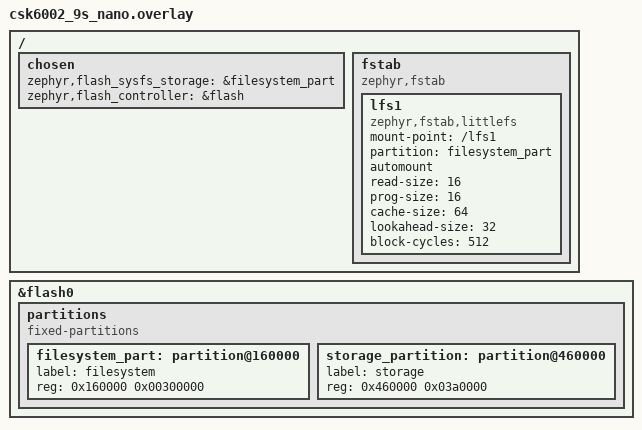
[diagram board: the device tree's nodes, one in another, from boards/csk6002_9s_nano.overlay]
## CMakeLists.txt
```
#
# Copyright (c) 2019 Peter Bigot Consulting, LLC
#
# SPDX-License-Identifier: Apache-2.0
#

cmake_minimum_required(VERSION 3.20.0)

set(SUPPORT_BOARDS csk6012_nano csk6011a_nano)
if(NOT ${BOARD} IN_LIST SUPPORT_BOARDS)
    message("Please choose one of the following boards:")
    foreach(item ${SUPPORT_BOARDS})
        message(STATUS ${item})
    endforeach()
    message(FATAL_ERROR "\nThe project does not support the ${BOARD}")
endif()

find_package(Zephyr REQUIRED HINTS $ENV{ZEPHYR_BASE})
project(littlefs)

# add_subdirectory(csk_sqlite3)

FILE(GLOB app_sources src/*.c)
target_sources(app PRIVATE ${app_sources})
```

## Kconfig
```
# Copyright (c) 2019 Peter Bigot Consulting, LLC
# SPDX-License-Identifier: Apache-2.0

mainmenu "littlefs sample"

config APP_WIPE_STORAGE
	bool "Option to clear the flash area before mounting"
	help
	  Use this to force an existing file system to be created.

config CSK_SQLITE
	bool "CSK_SQLITE3 support"

source "Kconfig.zephyr"
```

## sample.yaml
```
sample:
  description: sqlite3_littefs sample, the simplest Zephyr
    application
  name: sqlite3_littefs
tests:
  sample.board.csk6.subsys.sqlite3_littefs:
    tags: csk6
    platform_allow: csk6012_c3_nano
    harness: console
    timeout: 20
    harness_config:
      type: multi_line
      regex:
        - "CSK sqlite3 test complete!"
```

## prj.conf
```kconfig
#
# Copyright (c) 2019 Peter Bigot Consulting, LLC
#
# SPDX-License-Identifier: Apache-2.0
#
CONFIG_MAIN_STACK_SIZE=4096
CONFIG_CSK_HEAP=y
CONFIG_HEAP_MEM_POOL_SIZE=92160
CONFIG_DEBUG=y

CONFIG_LOG=y

CONFIG_FLASH=y
CONFIG_FLASH_MAP=y
CONFIG_FLASH_PAGE_LAYOUT=y

CONFIG_FILE_SYSTEM=y
CONFIG_FILE_SYSTEM_LITTLEFS=y
CONFIG_CSK_SQLITE=y

CONFIG_ENTROPY_GENERATOR=y
CONFIG_ENTROPY_CSK6_RNG=y

CONFIG_PRINTK_SYNC=y
```

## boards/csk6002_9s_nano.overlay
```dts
/*
 * Copyright (c) 2020 Circuit Dojo LLC
 *
 * SPDX-License-Identifier: Apache-2.0
 */

/delete-node/ &storage_partition;

/ {
	chosen {
		/*
		 * shared memory reserved for the inter-processor communication
		 */
		zephyr,flash_sysfs_storage = &filesystem_part;
		zephyr,flash_controller = &flash;
	};
	
	fstab {
		compatible = "zephyr,fstab";
		lfs1: lfs1 {
			compatible = "zephyr,fstab,littlefs";
			mount-point = "/lfs1";
			partition = <&filesystem_part>;
			automount ;
			// no-format;
			read-size = <16>;
			prog-size = <16>;
			cache-size = <64>;
			lookahead-size = <32>;
			block-cycles = <512>;
		};
	};

};

 
&flash0 {
	partitions {
		compatible = "fixed-partitions";
		#address-cells = <1>;
		#size-cells = <1>;
		filesystem_part: partition@160000 {
			label = "filesystem";
			reg = <0x160000 0x00300000>;
		};
		/*
		 * Reserve the final 640 KiB for file system partition
		 */
		storage_partition: partition@460000 {
			label = "storage";
			reg = <0x460000 0x03a0000>;
		};


	};
};
```

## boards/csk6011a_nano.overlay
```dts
/*
 * Copyright (c) 2023 Anhui(Shenzhen) Listenai Co., Ltd.
 *
 * SPDX-License-Identifier: Apache-2.0
 */
/delete-node/ &storage_partition;

/ {
	chosen {
		/*
		 * shared memory reserved for the inter-processor communication
		 */
		zephyr,flash_sysfs_storage = &filesystem_part;
		zephyr,flash_controller = &flash;
	};

	fstab {
		compatible = "zephyr,fstab";
		lfs1: lfs1 {
			compatible = "zephyr,fstab,littlefs";
			mount-point = "/lfs1";
			partition = <&filesystem_part>;
			automount ;
			// no-format;
			read-size = <16>;
			prog-size = <16>;
			cache-size = <64>;
			lookahead-size = <32>;
			block-cycles = <512>;
		};
	};

};


&flash0 {
	partitions {
		compatible = "fixed-partitions";
		#address-cells = <1>;
		#size-cells = <1>;
		filesystem_part: partition@160000 {
			label = "filesystem";
			reg = <0x160000 0x00300000>;
		};
		/*
		 * Reserve the final 640 KiB for file system partition
		 */
		storage_partition: partition@460000 {
			label = "storage";
			reg = <0x460000 0x03a0000>;
		};


	};
};
```

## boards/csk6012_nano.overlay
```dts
/*
 * Copyright (c) 2023 Anhui(Shenzhen) Listenai Co., Ltd.
 *
 * SPDX-License-Identifier: Apache-2.0
 */

/delete-node/ &storage_partition;

/ {
	chosen {
		/*
		 * shared memory reserved for the inter-processor communication
		 */
		zephyr,flash_sysfs_storage = &filesystem_part;
		zephyr,flash_controller = &flash;
	};

	fstab {
		compatible = "zephyr,fstab";
		lfs1: lfs1 {
			compatible = "zephyr,fstab,littlefs";
			mount-point = "/lfs1";
			partition = <&filesystem_part>;
			automount ;
			// no-format;
			read-size = <16>;
			prog-size = <16>;
			cache-size = <64>;
			lookahead-size = <32>;
			block-cycles = <512>;
		};
	};

};


&flash0 {
	partitions {
		compatible = "fixed-partitions";
		#address-cells = <1>;
		#size-cells = <1>;
		filesystem_part: partition@160000 {
			label = "filesystem";
			reg = <0x160000 0x00300000>;
		};
		/*
		 * Reserve the final 640 KiB for file system partition
		 */
		storage_partition: partition@460000 {
			label = "storage";
			reg = <0x460000 0x03a0000>;
		};


	};
};
```

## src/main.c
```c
/*
 * Copyright (c) 2023 Anhui(Shenzhen) Listenai Co., Ltd.
 *
 * SPDX-License-Identifier: Apache-2.0
 */
/* Sample which uses the filesystem API with littlefs */

#include "sqlite3.h"

#include <stdio.h>

#include <device.h>
#include <fs/fs.h>
#include <fs/littlefs.h>
#include <storage/flash_map.h>
#include <zephyr.h>

/* Matches LFS_NAME_MAX */
#define MAX_PATH_LEN 255

#define PARTITION_NODE DT_NODELABEL(lfs1)

#if DT_NODE_EXISTS(PARTITION_NODE)
FS_FSTAB_DECLARE_ENTRY(PARTITION_NODE);
#else  /* PARTITION_NODE */
FS_LITTLEFS_DECLARE_DEFAULT_CONFIG(storage);
static struct fs_mount_t lfs_storage_mnt = {
	.type = FS_LITTLEFS,
	.fs_data = &storage,
	.storage_dev = (void *)FLASH_AREA_ID(storage),
	.mnt_point = "/lfs",
};
#endif /* PARTITION_NODE */

const char *data = "Callback function called";
static int callback(void *data, int argc, char **argv, char **azColName)
{
	int i;
	printk("%s: ", (const char *)data);
	for (i = 0; i < argc; i++) {
		printk("%s = %s\n", azColName[i], argv[i] ? argv[i] : "NULL");
	}
	printk("\n");
	return 0;
}

int db_open(const char *filename, sqlite3 **db)
{
	int rc = sqlite3_open(filename, db);
	if (rc) {
		printk("Can't open database: %s\n", sqlite3_errmsg(*db));
		return rc;
	} else {
		printk("Opened database successfully\n");
	}
	return rc;
}

char *zErrMsg = 0;
int db_exec(sqlite3 *db, const char *sql)
{
	printk("%s\n", sql);

	uint32_t start = k_cycle_get_32();
	int rc = sqlite3_exec(db, sql, callback, (void *)data, &zErrMsg);
	if (rc != SQLITE_OK) {
		printk("SQL error: %s\n", zErrMsg);
		sqlite3_free(zErrMsg);
	} else {
		printk("Operation done successfully\n");
	}
	uint32_t time =
		(double)(k_cycle_get_32() - start) / sys_clock_hw_cycles_per_sec() * 1000 * 1000;
	printk("Time taken: %d us\n", time);
	return rc;
}

void main(void)
{
	sqlite3 *db1;
	sqlite3 *db2;
	struct fs_mount_t *mp =
#if DT_NODE_EXISTS(PARTITION_NODE)
		&FS_FSTAB_ENTRY(PARTITION_NODE)
#else
		&lfs_storage_mnt
#endif
		;
	int rc = 0;
	/* Do not mount if auto-mount has been enabled */
#if !DT_NODE_EXISTS(PARTITION_NODE) ||                                                             \
	!(FSTAB_ENTRY_DT_MOUNT_FLAGS(PARTITION_NODE) & FS_MOUNT_FLAG_AUTOMOUNT)
	rc = fs_mount(mp);
	if (rc < 0) {
		printk("FAIL: mount id %" PRIuPTR " at %s: %d\n", (uintptr_t)mp->storage_dev,
		       mp->mnt_point, rc);
		return;
	}
	printk("%s mount: %d\n", mp->mnt_point, rc);
#else
	printk("%s automounted\n", mp->mnt_point);
#endif

	struct fs_file_t file;

	fs_file_t_init(&file);

	sqlite3_initialize();

	struct fs_dirent dirent;
	if (fs_stat("/lfs1/test1.db", &dirent) >= 0) {
		rc = fs_unlink("/lfs1/test1.db");
		printk("fs_unlink: rc = %d\n", rc);
	}
	if (fs_stat("/lfs1/test2.db", &dirent) >= 0) {
		rc = fs_unlink("/lfs1/test2.db");
		printk("fs_unlink: rc = %d\n", rc);
	}

	if (db_open("/lfs1/test1.db", &db1))
		return;
	if (db_open("/lfs1/test2.db", &db2))
		return;

	rc = db_exec(db1, "CREATE TABLE test1 (id INTEGER, content);");
	if (rc != SQLITE_OK) {
		sqlite3_close(db1);
		sqlite3_close(db2);
		return;
	}
	rc = db_exec(db2, "CREATE TABLE test2 (id INTEGER, content);");
	if (rc != SQLITE_OK) {
		sqlite3_close(db1);
		sqlite3_close(db2);
		return;
	}

	rc = db_exec(db1, "INSERT INTO test1 VALUES (1, 'Hello, World from test1');");
	if (rc != SQLITE_OK) {
		sqlite3_close(db1);
		sqlite3_close(db2);
		return;
	}
	// rc = db_exec(db1, "INSERT INTO test1 VALUES (2, 'over, World from test1');");
	// if (rc != SQLITE_OK) {
	// 	sqlite3_close(db1);
	// 	sqlite3_close(db2);
	// 	return;
	// }
	rc = db_exec(db2, "INSERT INTO test2 VALUES (1, 'Hello, World from test2');");
	if (rc != SQLITE_OK) {
		sqlite3_close(db1);
		sqlite3_close(db2);
		return;
	}

	rc = db_exec(db1, "SELECT * FROM test1");
	if (rc != SQLITE_OK) {
		sqlite3_close(db1);
		sqlite3_close(db2);
		return;
	}
	rc = db_exec(db2, "SELECT * FROM test2");
	if (rc != SQLITE_OK) {
		sqlite3_close(db1);
		sqlite3_close(db2);
		return;
	}

	sqlite3_close(db1);
	sqlite3_close(db2);

	rc = fs_unmount(mp);
	printk("%s unmount: %d\n", mp->mnt_point, rc);
	printk("CSK sqlite3 test complete!\n");
}
```

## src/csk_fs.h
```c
#ifndef __CSK_FS_H__
#define __CSK_FS_H__

#include <fs/fs.h>
#include <fs/littlefs.h>

#endif 
```
